# COMPUTE_CLUSTER0_CFG_WRAP_0_CC register map
Vendor: Texas Instruments
Peripheral module from a debugger description file (folder J721S2).
Registers are 32-bit, read-write, reset 0x0 unless marked. A register's access mark holds for its fields unless they carry their own. Offsets are as the file gives them; lines under a group give offsets from that group; [hi:lo] are bit positions; {n}, {i} and the like mark numbered series; 'fields as' and 'values as' point back to an identical list; <NAME> marks a mode.

## COMPUTE_CLUSTER0_CFG_WRAP_0_CC
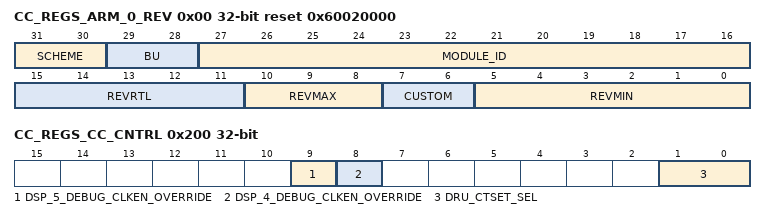
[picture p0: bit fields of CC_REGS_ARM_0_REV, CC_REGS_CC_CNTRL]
0x00 CC_REGS_ARM_0_REV ro reset 0x60020000 — ARM REVISION parameters
  [31:30] SCHEME
  [29:28] BU — Scheme
  [27:16] MODULE_ID
  [15:11] REVRTL — RTL version
  [10:8] REVMAX — Major version
  [7:6] CUSTOM — Custom version
  [5:0] REVMIN — Minor version
0x100 CC_REGS_ARM_0_PBIST_BISOR_CNTRL — ARM BISOR control register
  [0] CC_ARM0_DFT_SELF_REPAIR_MODE_OVERRIDE — bisor override for cpu0
0x200 CC_REGS_CC_CNTRL — CC misc control register
  [9] DSP_5_DEBUG_CLKEN_OVERRIDE — DSP I0/I1 clock gate override. Can be used to override DSP I0/I1 clock enables for debug on all instances. This bit has to set before AC71 powerup. 1 - Override I0/I1 clock enable on all DSP instances in compute cluster.
  [8] DSP_4_DEBUG_CLKEN_OVERRIDE — DSP I0/I1 clock gate override. Can be used to override DSP I0/I1 clock enables for debug on all instances. This bit has to set before AC71 powerup. 1 - Override I0/I1 clock enable on all DSP instances in compute cluster.
  [1:0] DRU_CTSET_SEL — DRU ctset mux control. 00 - DRU0 ctset and CMMU events are connected to debug_wrap hwdbg event. 01 - DRU1 ctset and CMMU events are connected to debug_wrap hwdbg event. 10 - Unused. 11 - Unused
